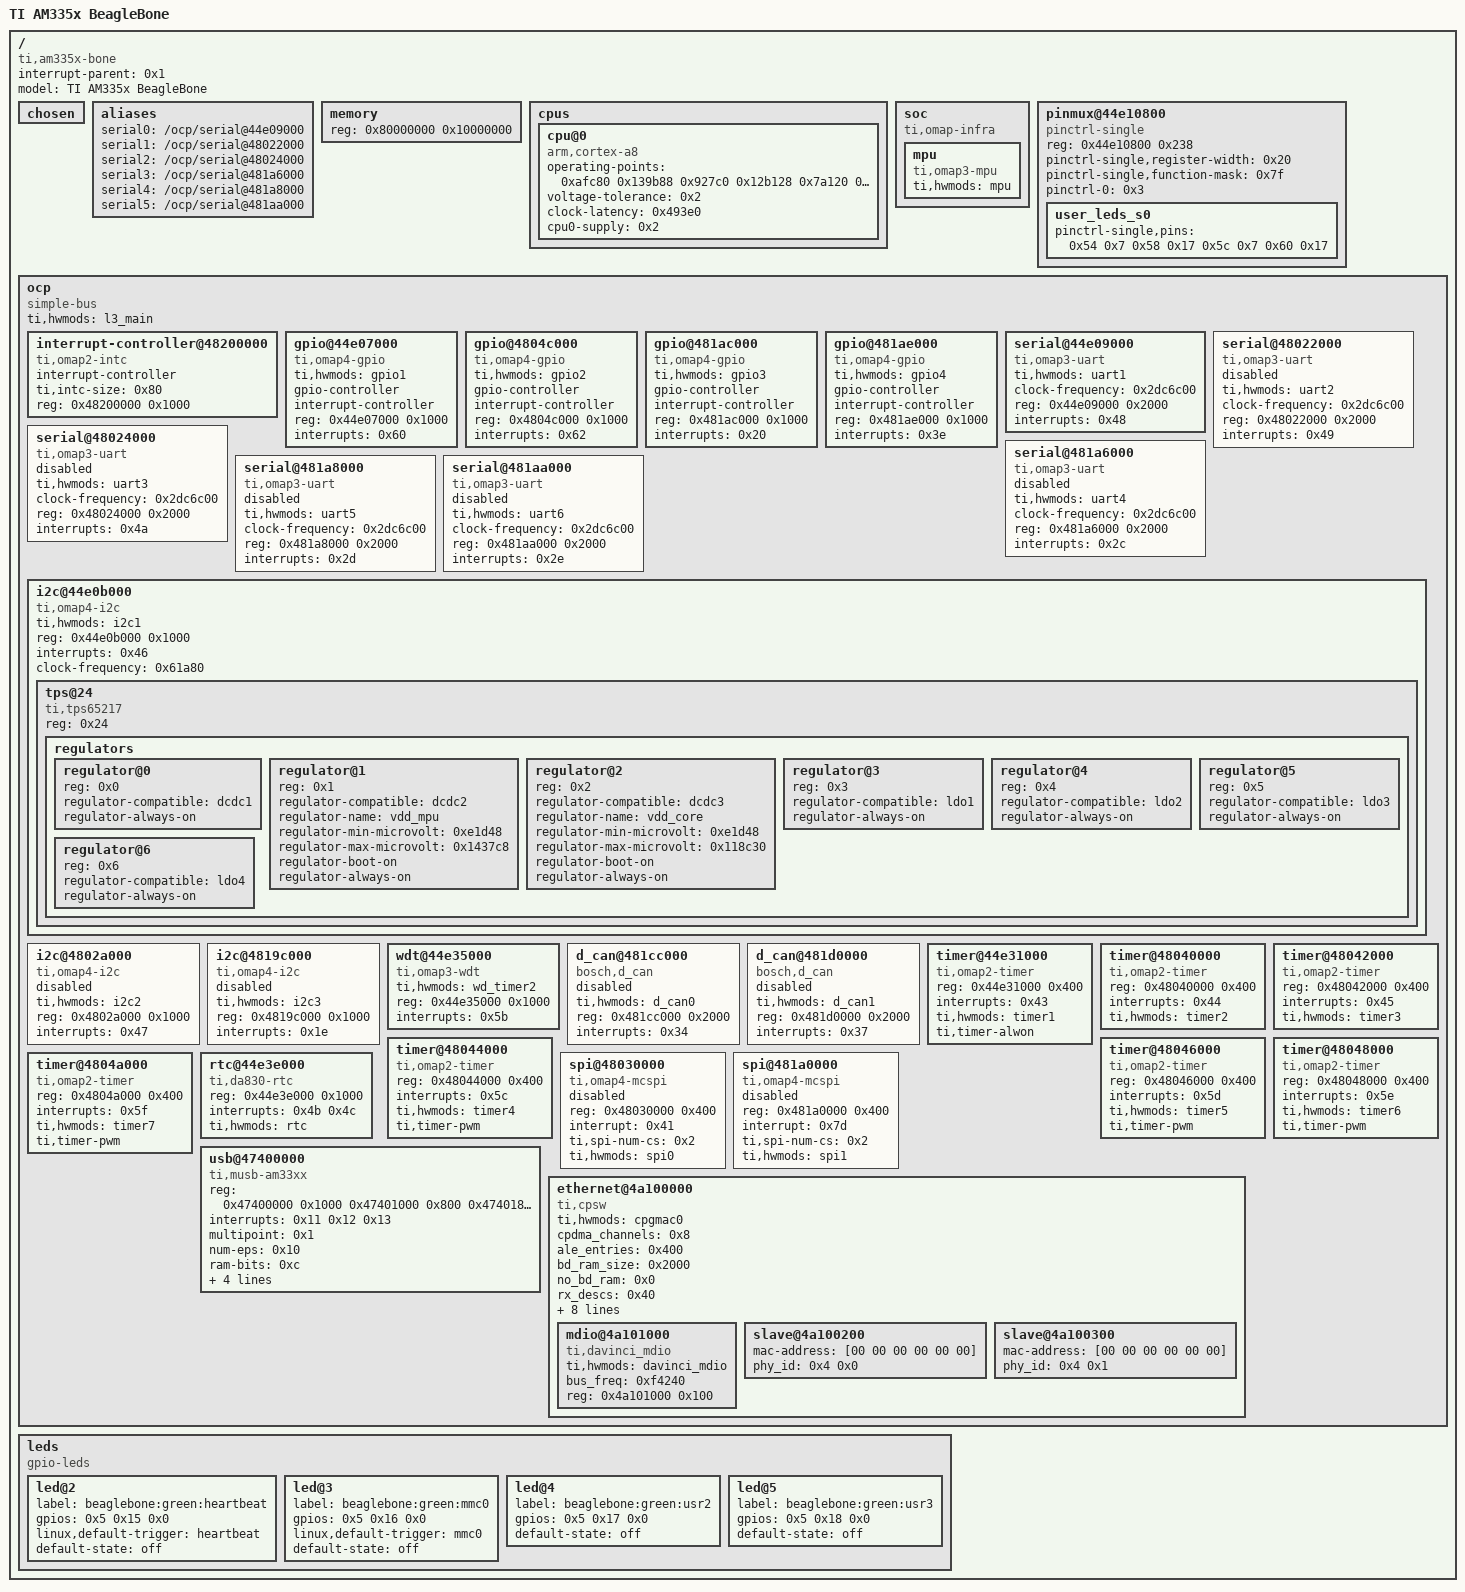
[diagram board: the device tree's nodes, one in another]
/dts-v1/;

/ {
	#address-cells = <0x1>;
	#size-cells = <0x1>;
	compatible = "ti,am335x-bone", "ti,am33xx";
	interrupt-parent = <0x1>;
	model = "TI AM335x BeagleBone";

	chosen {
	};

	aliases {
		serial0 = "/ocp/serial@44e09000";
		serial1 = "/ocp/serial@48022000";
		serial2 = "/ocp/serial@48024000";
		serial3 = "/ocp/serial@481a6000";
		serial4 = "/ocp/serial@481a8000";
		serial5 = "/ocp/serial@481aa000";
	};

	memory {
		device_type = "memory";
		reg = <0x80000000 0x10000000>;
	};

	cpus {

		cpu@0 {
			compatible = "arm,cortex-a8";
			operating-points = <0xafc80 0x139b88 0x927c0 0x12b128 0x7a120 0x112a88 0x43238 0x112a88>;
			voltage-tolerance = <0x2>;
			clock-latency = <0x493e0>;
			cpu0-supply = <0x2>;
		};
	};

	soc {
		compatible = "ti,omap-infra";

		mpu {
			compatible = "ti,omap3-mpu";
			ti,hwmods = "mpu";
		};
	};

	pinmux@44e10800 {
		compatible = "pinctrl-single";
		reg = <0x44e10800 0x238>;
		#address-cells = <0x1>;
		#size-cells = <0x0>;
		pinctrl-single,register-width = <0x20>;
		pinctrl-single,function-mask = <0x7f>;
		pinctrl-names = "default";
		pinctrl-0 = <0x3>;

		user_leds_s0 {
			pinctrl-single,pins = <0x54 0x7 0x58 0x17 0x5c 0x7 0x60 0x17>;
			linux,phandle = <0x3>;
			phandle = <0x3>;
		};
	};

	ocp {
		compatible = "simple-bus";
		#address-cells = <0x1>;
		#size-cells = <0x1>;
		ranges;
		ti,hwmods = "l3_main";

		interrupt-controller@48200000 {
			compatible = "ti,omap2-intc";
			interrupt-controller;
			#interrupt-cells = <0x1>;
			ti,intc-size = <0x80>;
			reg = <0x48200000 0x1000>;
			linux,phandle = <0x1>;
			phandle = <0x1>;
		};

		gpio@44e07000 {
			compatible = "ti,omap4-gpio";
			ti,hwmods = "gpio1";
			gpio-controller;
			#gpio-cells = <0x2>;
			interrupt-controller;
			#interrupt-cells = <0x1>;
			reg = <0x44e07000 0x1000>;
			interrupts = <0x60>;
		};

		gpio@4804c000 {
			compatible = "ti,omap4-gpio";
			ti,hwmods = "gpio2";
			gpio-controller;
			#gpio-cells = <0x2>;
			interrupt-controller;
			#interrupt-cells = <0x1>;
			reg = <0x4804c000 0x1000>;
			interrupts = <0x62>;
			linux,phandle = <0x5>;
			phandle = <0x5>;
		};

		gpio@481ac000 {
			compatible = "ti,omap4-gpio";
			ti,hwmods = "gpio3";
			gpio-controller;
			#gpio-cells = <0x2>;
			interrupt-controller;
			#interrupt-cells = <0x1>;
			reg = <0x481ac000 0x1000>;
			interrupts = <0x20>;
		};

		gpio@481ae000 {
			compatible = "ti,omap4-gpio";
			ti,hwmods = "gpio4";
			gpio-controller;
			#gpio-cells = <0x2>;
			interrupt-controller;
			#interrupt-cells = <0x1>;
			reg = <0x481ae000 0x1000>;
			interrupts = <0x3e>;
		};

		serial@44e09000 {
			compatible = "ti,omap3-uart";
			ti,hwmods = "uart1";
			clock-frequency = <0x2dc6c00>;
			reg = <0x44e09000 0x2000>;
			interrupts = <0x48>;
			status = "okay";
		};

		serial@48022000 {
			compatible = "ti,omap3-uart";
			ti,hwmods = "uart2";
			clock-frequency = <0x2dc6c00>;
			reg = <0x48022000 0x2000>;
			interrupts = <0x49>;
			status = "disabled";
		};

		serial@48024000 {
			compatible = "ti,omap3-uart";
			ti,hwmods = "uart3";
			clock-frequency = <0x2dc6c00>;
			reg = <0x48024000 0x2000>;
			interrupts = <0x4a>;
			status = "disabled";
		};

		serial@481a6000 {
			compatible = "ti,omap3-uart";
			ti,hwmods = "uart4";
			clock-frequency = <0x2dc6c00>;
			reg = <0x481a6000 0x2000>;
			interrupts = <0x2c>;
			status = "disabled";
		};

		serial@481a8000 {
			compatible = "ti,omap3-uart";
			ti,hwmods = "uart5";
			clock-frequency = <0x2dc6c00>;
			reg = <0x481a8000 0x2000>;
			interrupts = <0x2d>;
			status = "disabled";
		};

		serial@481aa000 {
			compatible = "ti,omap3-uart";
			ti,hwmods = "uart6";
			clock-frequency = <0x2dc6c00>;
			reg = <0x481aa000 0x2000>;
			interrupts = <0x2e>;
			status = "disabled";
		};

		i2c@44e0b000 {
			compatible = "ti,omap4-i2c";
			#address-cells = <0x1>;
			#size-cells = <0x0>;
			ti,hwmods = "i2c1";
			reg = <0x44e0b000 0x1000>;
			interrupts = <0x46>;
			status = "okay";
			clock-frequency = <0x61a80>;

			tps@24 {
				reg = <0x24>;
				compatible = "ti,tps65217";

				regulators {
					#address-cells = <0x1>;
					#size-cells = <0x0>;

					regulator@0 {
						reg = <0x0>;
						regulator-compatible = "dcdc1";
						regulator-always-on;
					};

					regulator@1 {
						reg = <0x1>;
						regulator-compatible = "dcdc2";
						regulator-name = "vdd_mpu";
						regulator-min-microvolt = <0xe1d48>;
						regulator-max-microvolt = <0x1437c8>;
						regulator-boot-on;
						regulator-always-on;
						linux,phandle = <0x2>;
						phandle = <0x2>;
					};

					regulator@2 {
						reg = <0x2>;
						regulator-compatible = "dcdc3";
						regulator-name = "vdd_core";
						regulator-min-microvolt = <0xe1d48>;
						regulator-max-microvolt = <0x118c30>;
						regulator-boot-on;
						regulator-always-on;
					};

					regulator@3 {
						reg = <0x3>;
						regulator-compatible = "ldo1";
						regulator-always-on;
					};

					regulator@4 {
						reg = <0x4>;
						regulator-compatible = "ldo2";
						regulator-always-on;
					};

					regulator@5 {
						reg = <0x5>;
						regulator-compatible = "ldo3";
						regulator-always-on;
					};

					regulator@6 {
						reg = <0x6>;
						regulator-compatible = "ldo4";
						regulator-always-on;
					};
				};
			};
		};

		i2c@4802a000 {
			compatible = "ti,omap4-i2c";
			#address-cells = <0x1>;
			#size-cells = <0x0>;
			ti,hwmods = "i2c2";
			reg = <0x4802a000 0x1000>;
			interrupts = <0x47>;
			status = "disabled";
		};

		i2c@4819c000 {
			compatible = "ti,omap4-i2c";
			#address-cells = <0x1>;
			#size-cells = <0x0>;
			ti,hwmods = "i2c3";
			reg = <0x4819c000 0x1000>;
			interrupts = <0x1e>;
			status = "disabled";
		};

		wdt@44e35000 {
			compatible = "ti,omap3-wdt";
			ti,hwmods = "wd_timer2";
			reg = <0x44e35000 0x1000>;
			interrupts = <0x5b>;
		};

		d_can@481cc000 {
			compatible = "bosch,d_can";
			ti,hwmods = "d_can0";
			reg = <0x481cc000 0x2000>;
			interrupts = <0x34>;
			status = "disabled";
		};

		d_can@481d0000 {
			compatible = "bosch,d_can";
			ti,hwmods = "d_can1";
			reg = <0x481d0000 0x2000>;
			interrupts = <0x37>;
			status = "disabled";
		};

		timer@44e31000 {
			compatible = "ti,omap2-timer";
			reg = <0x44e31000 0x400>;
			interrupts = <0x43>;
			ti,hwmods = "timer1";
			ti,timer-alwon;
		};

		timer@48040000 {
			compatible = "ti,omap2-timer";
			reg = <0x48040000 0x400>;
			interrupts = <0x44>;
			ti,hwmods = "timer2";
		};

		timer@48042000 {
			compatible = "ti,omap2-timer";
			reg = <0x48042000 0x400>;
			interrupts = <0x45>;
			ti,hwmods = "timer3";
		};

		timer@48044000 {
			compatible = "ti,omap2-timer";
			reg = <0x48044000 0x400>;
			interrupts = <0x5c>;
			ti,hwmods = "timer4";
			ti,timer-pwm;
		};

		timer@48046000 {
			compatible = "ti,omap2-timer";
			reg = <0x48046000 0x400>;
			interrupts = <0x5d>;
			ti,hwmods = "timer5";
			ti,timer-pwm;
		};

		timer@48048000 {
			compatible = "ti,omap2-timer";
			reg = <0x48048000 0x400>;
			interrupts = <0x5e>;
			ti,hwmods = "timer6";
			ti,timer-pwm;
		};

		timer@4804a000 {
			compatible = "ti,omap2-timer";
			reg = <0x4804a000 0x400>;
			interrupts = <0x5f>;
			ti,hwmods = "timer7";
			ti,timer-pwm;
		};

		rtc@44e3e000 {
			compatible = "ti,da830-rtc";
			reg = <0x44e3e000 0x1000>;
			interrupts = <0x4b 0x4c>;
			ti,hwmods = "rtc";
		};

		spi@48030000 {
			compatible = "ti,omap4-mcspi";
			#address-cells = <0x1>;
			#size-cells = <0x0>;
			reg = <0x48030000 0x400>;
			interrupt = <0x41>;
			ti,spi-num-cs = <0x2>;
			ti,hwmods = "spi0";
			status = "disabled";
		};

		spi@481a0000 {
			compatible = "ti,omap4-mcspi";
			#address-cells = <0x1>;
			#size-cells = <0x0>;
			reg = <0x481a0000 0x400>;
			interrupt = <0x7d>;
			ti,spi-num-cs = <0x2>;
			ti,hwmods = "spi1";
			status = "disabled";
		};

		usb@47400000 {
			compatible = "ti,musb-am33xx";
			reg = <0x47400000 0x1000 0x47401000 0x800 0x47401800 0x800>;
			interrupts = <0x11 0x12 0x13>;
			multipoint = <0x1>;
			num-eps = <0x10>;
			ram-bits = <0xc>;
			port0-mode = <0x3>;
			port1-mode = <0x3>;
			power = <0xfa>;
			ti,hwmods = "usb_otg_hs";
		};

		ethernet@4a100000 {
			compatible = "ti,cpsw";
			ti,hwmods = "cpgmac0";
			cpdma_channels = <0x8>;
			ale_entries = <0x400>;
			bd_ram_size = <0x2000>;
			no_bd_ram = <0x0>;
			rx_descs = <0x40>;
			mac_control = <0x20>;
			slaves = <0x2>;
			cpts_active_slave = <0x0>;
			cpts_clock_mult = <0x80000000>;
			cpts_clock_shift = <0x1d>;
			reg = <0x4a100000 0x800 0x4a101200 0x100>;
			#address-cells = <0x1>;
			#size-cells = <0x1>;
			interrupt-parent = <0x1>;
			interrupts = <0x28 0x29 0x2a 0x2b>;
			ranges;

			mdio@4a101000 {
				compatible = "ti,davinci_mdio";
				#address-cells = <0x1>;
				#size-cells = <0x0>;
				ti,hwmods = "davinci_mdio";
				bus_freq = <0xf4240>;
				reg = <0x4a101000 0x100>;
				linux,phandle = <0x4>;
				phandle = <0x4>;
			};

			slave@4a100200 {
				mac-address = [00 00 00 00 00 00];
				phy_id = <0x4 0x0>;
			};

			slave@4a100300 {
				mac-address = [00 00 00 00 00 00];
				phy_id = <0x4 0x1>;
			};
		};
	};

	leds {
		compatible = "gpio-leds";

		led@2 {
			label = "beaglebone:green:heartbeat";
			gpios = <0x5 0x15 0x0>;
			linux,default-trigger = "heartbeat";
			default-state = "off";
		};

		led@3 {
			label = "beaglebone:green:mmc0";
			gpios = <0x5 0x16 0x0>;
			linux,default-trigger = "mmc0";
			default-state = "off";
		};

		led@4 {
			label = "beaglebone:green:usr2";
			gpios = <0x5 0x17 0x0>;
			default-state = "off";
		};

		led@5 {
			label = "beaglebone:green:usr3";
			gpios = <0x5 0x18 0x0>;
			default-state = "off";
		};
	};
};
